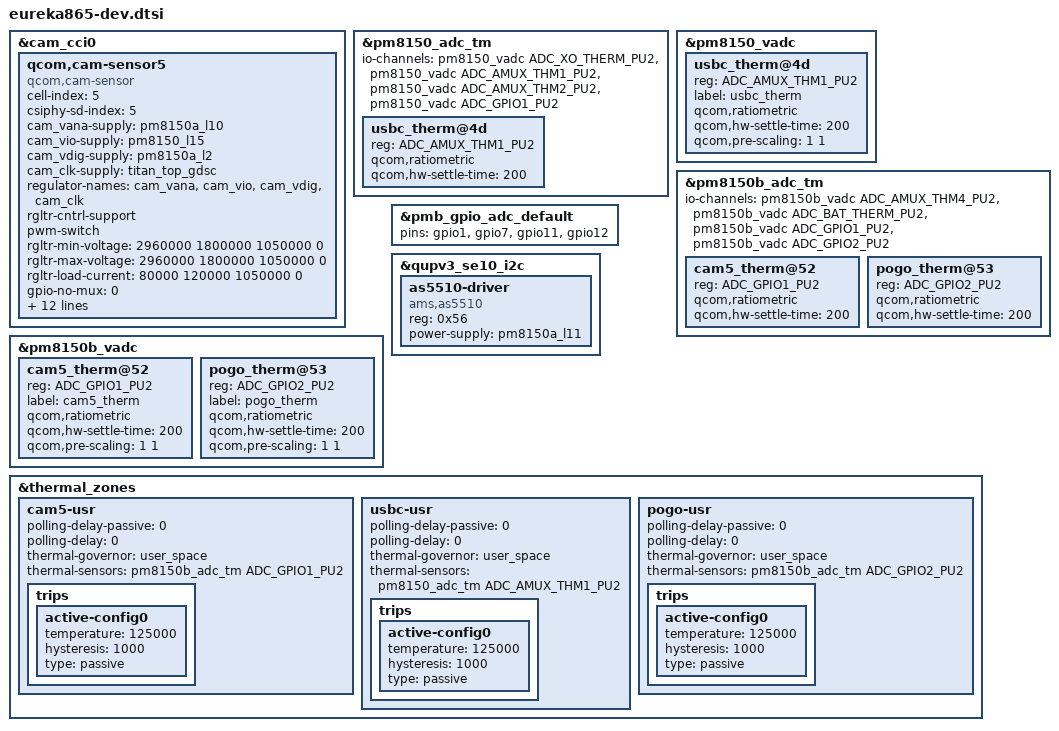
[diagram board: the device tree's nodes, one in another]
// SPDX-License-Identifier: GPL-2.0

&cam_cci0 {
	qcom,cam-sensor5 {
		/* CAMERA ID = 5
		 * name: CAM_RGB2
		 * QCOM CSI PHY = 5
		 * QCOM MCLK = 6
		 */
		cell-index = <5>;
		compatible = "qcom,cam-sensor";
		csiphy-sd-index = <5>;
		/* T97436334: Regulators are intentionally misnamed */
		cam_vana-supply = <&pm8150a_l10>;
		cam_vio-supply = <&pm8150_l15>;
		cam_vdig-supply = <&pm8150a_l2>;
		cam_clk-supply = <&titan_top_gdsc>;
		regulator-names = "cam_vana", "cam_vio", "cam_vdig",
			"cam_clk";
		rgltr-cntrl-support;
		pwm-switch;
		rgltr-min-voltage = <2960000 1800000 1050000 0>;
		rgltr-max-voltage = <2960000 1800000 1050000 0>;
		rgltr-load-current = <80000 120000 1050000 0>;
		gpio-no-mux = <0>;
		pinctrl-names = "cam_default", "cam_suspend";
		pinctrl-0 = <&cam_sensor_mclk6_active>;
		pinctrl-1 = <&cam_sensor_mclk6_suspend>;
		gpios = <&tlmm 100 0>;
		gpio-req-tbl-num = <0>;
		gpio-req-tbl-flags = <1>;
		gpio-req-tbl-label = "CAMIF_MCLK6";
		sensor-mode = <0>;
		cci-master = <1>;
		clocks = <&clock_camcc CAM_CC_MCLK6_CLK>;
		clock-names = "cam_clk";
		clock-cntl-level = "turbo";
		clock-rates = <19200000>;
		oculus,cam-mclk-no-power-down;
	};
};

&pm8150_adc_tm {
	io-channels = <&pm8150_vadc ADC_XO_THERM_PU2>,
		<&pm8150_vadc ADC_AMUX_THM1_PU2>,
		<&pm8150_vadc ADC_AMUX_THM2_PU2>,
		<&pm8150_vadc ADC_GPIO1_PU2>;

	usbc_therm@4d {
		reg = <ADC_AMUX_THM1_PU2>;
		qcom,ratiometric;
		qcom,hw-settle-time = <200>;
	};
};

&pm8150_vadc {
	usbc_therm@4d {
		reg = <ADC_AMUX_THM1_PU2>;
		label = "usbc_therm";
		qcom,ratiometric;
		qcom,hw-settle-time = <200>;
		qcom,pre-scaling = <1 1>;
	};
};

&pm8150b_adc_tm {
	io-channels = <&pm8150b_vadc ADC_AMUX_THM4_PU2>,
		<&pm8150b_vadc ADC_BAT_THERM_PU2>,
		<&pm8150b_vadc ADC_GPIO1_PU2>,
		<&pm8150b_vadc ADC_GPIO2_PU2>;

	cam5_therm@52 {
		/* RGB camera R */
		reg = <ADC_GPIO1_PU2>;
		qcom,ratiometric;
		qcom,hw-settle-time = <200>;
	};

	pogo_therm@53 {
		reg = <ADC_GPIO2_PU2>;
		qcom,ratiometric;
		qcom,hw-settle-time = <200>;
	};
};

&pm8150b_vadc {
	cam5_therm@52 {
		/* RGB camera R */
		reg = <ADC_GPIO1_PU2>;
		label = "cam5_therm";
		qcom,ratiometric;
		qcom,hw-settle-time = <200>;
		qcom,pre-scaling = <1 1>;
	};

	pogo_therm@53 {
		reg = <ADC_GPIO2_PU2>;
		label = "pogo_therm";
		qcom,ratiometric;
		qcom,hw-settle-time = <200>;
		qcom,pre-scaling = <1 1>;
	};
};

&pmb_gpio_adc_default {
	pins = "gpio1", "gpio7", "gpio11", "gpio12";
};

&qupv3_se10_i2c {
	as5510-driver {
		reg = <0x56>;
		compatible = "ams,as5510";
		power-supply = <&pm8150a_l11>;
	};
};

&thermal_zones {
	cam5-usr {
		/* RGB camera R */
		polling-delay-passive = <0>;
		polling-delay = <0>;
		thermal-governor = "user_space";
		thermal-sensors = <&pm8150b_adc_tm ADC_GPIO1_PU2>;
		trips {
			active-config0 {
				temperature = <125000>;
				hysteresis = <1000>;
				type = "passive";
			};
		};
	};

	usbc-usr {
		polling-delay-passive = <0>;
		polling-delay = <0>;
		thermal-governor = "user_space";
		thermal-sensors = <&pm8150_adc_tm ADC_AMUX_THM1_PU2>;
		trips {
			active-config0 {
				temperature = <125000>;
				hysteresis = <1000>;
				type = "passive";
			};
		};
	};

	pogo-usr {
		polling-delay-passive = <0>;
		polling-delay = <0>;
		thermal-governor = "user_space";
		thermal-sensors = <&pm8150b_adc_tm ADC_GPIO2_PU2>;
		trips {
			active-config0 {
				temperature = <125000>;
				hysteresis = <1000>;
				type = "passive";
			};
		};
	};
};
